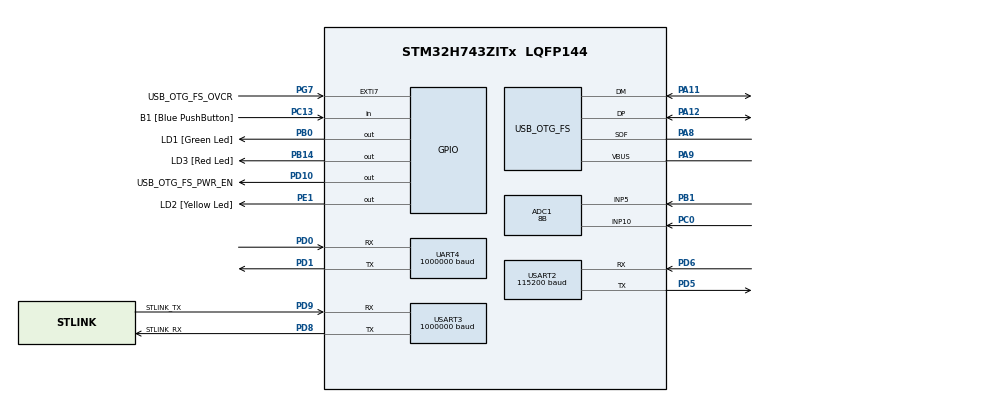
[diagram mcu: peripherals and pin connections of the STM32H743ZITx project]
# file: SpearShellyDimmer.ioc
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ADC1.Channel-0\#ChannelRegularConversion=ADC_CHANNEL_10
ADC1.Channel-1\#ChannelRegularConversion=ADC_CHANNEL_5
ADC1.ClockPrescaler=ADC_CLOCK_ASYNC_DIV8
ADC1.ContinuousConvMode=ENABLE
ADC1.ConversionDataManagement=ADC_CONVERSIONDATA_DMA_ONESHOT
ADC1.NbrOfConversion=2
ADC1.NbrOfConversionFlag=1
ADC1.OffsetNumber-0\#ChannelRegularConversion=ADC_OFFSET_NONE
ADC1.OffsetNumber-1\#ChannelRegularConversion=ADC_OFFSET_NONE
ADC1.OffsetSignedSaturation-0\#ChannelRegularConversion=DISABLE
ADC1.OffsetSignedSaturation-1\#ChannelRegularConversion=DISABLE
ADC1.Rank-0\#ChannelRegularConversion=1
ADC1.Rank-1\#ChannelRegularConversion=2
ADC1.Resolution=ADC_RESOLUTION_8B
ADC1.SamplingTime-0\#ChannelRegularConversion=ADC_SAMPLETIME_2CYCLES_5
ADC1.SamplingTime-1\#ChannelRegularConversion=ADC_SAMPLETIME_2CYCLES_5
ADC1.master=1
CORTEX_M7.CPU_DCache=Enabled
CORTEX_M7.CPU_ICache=Enabled
Dma.ADC1.0.Direction=DMA_PERIPH_TO_MEMORY
Dma.ADC1.0.EventEnable=DISABLE
Dma.ADC1.0.FIFOMode=DMA_FIFOMODE_DISABLE
Dma.ADC1.0.Instance=DMA1_Stream1
Dma.ADC1.0.MemDataAlignment=DMA_MDATAALIGN_HALFWORD
Dma.ADC1.0.MemInc=DMA_MINC_ENABLE
Dma.ADC1.0.Mode=DMA_NORMAL
Dma.ADC1.0.PeriphDataAlignment=DMA_PDATAALIGN_HALFWORD
Dma.ADC1.0.PeriphInc=DMA_PINC_DISABLE
Dma.ADC1.0.Polarity=HAL_DMAMUX_REQ_GEN_RISING
Dma.ADC1.0.Priority=DMA_PRIORITY_LOW
Dma.ADC1.0.RequestNumber=1
Dma.ADC1.0.SignalID=NONE
Dma.ADC1.0.SyncEnable=DISABLE
Dma.ADC1.0.SyncPolarity=HAL_DMAMUX_SYNC_NO_EVENT
Dma.ADC1.0.SyncRequestNumber=1
Dma.ADC1.0.SyncSignalID=NONE
Dma.Request0=ADC1
Mcu.Family=STM32H7
Mcu.Name=STM32H743ZITx
Mcu.Package=LQFP144
NVIC.DMA1_Stream1_IRQn=true\:0\:0\:false\:false\:true\:false\:true\:true
NVIC.OTG_FS_IRQn=true\:5\:0\:true\:false\:true\:false\:true\:true
NVIC.PriorityGroup=NVIC_PRIORITYGROUP_4
NVIC.TIM17_IRQn=true\:15\:0\:false\:false\:true\:false\:true\:true
NVIC.TIM3_IRQn=true\:0\:0\:false\:false\:true\:true\:true\:true
NVIC.TimeBase=TIM17_IRQn
NVIC.TimeBaseIP=TIM17
NVIC.UART4_IRQn=true\:6\:0\:true\:false\:true\:true\:true\:true
NVIC.USART2_IRQn=true\:6\:0\:true\:false\:true\:true\:true\:true
PA1.Signal=ETH_REF_CLK
PA11.Mode=Device_Only
PA11.Signal=USB_OTG_FS_DM
PA12.Mode=Device_Only
PA12.Signal=USB_OTG_FS_DP
PA2.Signal=ETH_MDIO
PA7.Signal=ETH_CRS_DV
PA8.Mode=Activate_SOF_FS
PA8.Signal=USB_OTG_FS_SOF
PA9.Mode=Activate_VBUS
PA9.Signal=USB_OTG_FS_VBUS
PB0.GPIO_Label=LD1 [Green Led]
PB0.Signal=GPIO_Output
PB1.Signal=ADCx_INP5
PB13.Signal=ETH_TXD1
PB14.GPIO_Label=LD3 [Red Led]
PB14.Signal=GPIO_Output
PC0.Signal=ADCx_INP10
PC1.Signal=ETH_MDC
PC13.GPIO_Label=B1 [Blue PushButton]
PC13.Signal=GPIO_Input
PC14-OSC32_IN\ (OSC32_IN).Mode=LSE-External-Oscillator
PC14-OSC32_IN\ (OSC32_IN).Signal=RCC_OSC32_IN
PC15-OSC32_OUT\ (OSC32_OUT).Mode=LSE-External-Oscillator
PC15-OSC32_OUT\ (OSC32_OUT).Signal=RCC_OSC32_OUT
PC4.Signal=ETH_RXD0
PC5.Signal=ETH_RXD1
PD0.Mode=Asynchronous
PD0.Signal=UART4_RX
PD1.Mode=Asynchronous
PD1.Signal=UART4_TX
PD10.GPIO_Label=USB_OTG_FS_PWR_EN
PD10.Signal=GPIO_Output
PD5.Mode=Asynchronous
PD5.Signal=USART2_TX
PD6.Mode=Asynchronous
PD6.Signal=USART2_RX
PD8.GPIO_Label=STLINK_RX
PD8.Mode=Asynchronous
PD8.Signal=USART3_TX
PD9.GPIO_Label=STLINK_TX
PD9.Mode=Asynchronous
PD9.Signal=USART3_RX
PE1.GPIO_Label=LD2 [Yellow Led]
PE1.Signal=GPIO_Output
PG11.Signal=ETH_TX_EN
PG13.Signal=ETH_TXD0
PG7.GPIO_Label=USB_OTG_FS_OVCR
PG7.Signal=GPXTI7
PH0-OSC_IN\ (PH0).Mode=HSE-External-Clock-Source
PH0-OSC_IN\ (PH0).Signal=RCC_OSC_IN
PH1-OSC_OUT\ (PH1).Signal=RCC_OSC_OUT
ProjectManager.HeapSize=0x200
ProjectManager.StackSize=0x400
ProjectManager.TargetToolchain=STM32CubeIDE
RCC.ADCFreq_Value=76000000
RCC.APB1Freq_Value=120000000
RCC.APB2Freq_Value=120000000
RCC.APB3Freq_Value=120000000
RCC.APB4Freq_Value=120000000
RCC.CortexFreq_Value=480000000
RCC.D1PPRE=RCC_APB3_DIV2
RCC.D2PPRE1=RCC_APB1_DIV2
RCC.D2PPRE2=RCC_APB2_DIV2
RCC.D3PPRE=RCC_APB4_DIV2
RCC.DIVM1=1
RCC.DIVM2=1
RCC.DIVN1=120
RCC.DIVN2=19
RCC.HCLKFreq_Value=240000000
RCC.HPRE=RCC_HCLK_DIV2
RCC.HSE_VALUE=8000000
RCC.PLL2FRACN=0
RCC.PLL3FRACN=0
RCC.PLLFRACN=0
RCC.PLLSourceVirtual=RCC_PLLSOURCE_HSE
RCC.PWR_Regulator_Voltage_Scale=PWR_REGULATOR_VOLTAGE_SCALE0
RCC.SYSCLKFreq_VALUE=480000000
RCC.SYSCLKSource=RCC_SYSCLKSOURCE_PLLCLK
RCC.USBCLockSelection=RCC_USBCLKSOURCE_HSI48
RCC.USBFreq_Value=48000000
SH.ADCx_INP10.0=ADC1_INP10,IN10-Single-Ended
SH.ADCx_INP5.0=ADC1_INP5,IN5-Single-Ended
TIM3.AutoReloadPreload=TIM_AUTORELOAD_PRELOAD_ENABLE
TIM3.Channel-Output\ Compare1\ No\ Output=TIM_CHANNEL_1
TIM3.Period=10
TIM3.Prescaler=4800
TIM3.Pulse-Output\ Compare1\ No\ Output=5
UART4.BaudRate=1000000
UART4.FIFOMode=FIFOMODE_DISABLE
UART4.Mode=MODE_TX_RX
USART2.BaudRate=115200
USART2.Mode=MODE_TX_RX
USART2.VirtualMode-Asynchronous=VM_ASYNC
USART3.BaudRate=1000000
USART3.VirtualMode-Asynchronous=VM_ASYNC
USB_DEVICE.CLASS_NAME_FS=CDC
USB_DEVICE.USBD_MAX_NUM_INTERFACES-CDC_FS=1
USB_DEVICE.VirtualMode-CDC_FS=Cdc
USB_DEVICE.VirtualModeFS=Cdc_FS
USB_OTG_FS.VirtualMode=Device_Only
VP_SYS_VS_tim17.Mode=TIM17
VP_TIM3_VS_ClockSourceINT.Mode=Internal
VP_TIM3_VS_no_output1.Mode=Output Compare1 No Output
VP_USB_DEVICE_VS_USB_DEVICE_CDC_FS.Mode=CDC_FS
board=NUCLEO-H743ZI2

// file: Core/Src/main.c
/* USER CODE BEGIN Header */
/**
  ******************************************************************************
  * @file           : main.c
  * @brief          : Main program body
  ******************************************************************************
  * @attention
  *
  * <h2><center>&copy; Copyright (c) 2022 STMicroelectronics.
  * All rights reserved.</center></h2>
  *
  * This software component is licensed by ST under BSD 3-Clause license,
  * the "License"; You may not use this file except in compliance with the
  * License. You may obtain a copy of the License at:
  *                        opensource.org/licenses/BSD-3-Clause
  *
  ******************************************************************************
  */
/* USER CODE END Header */
#include "main.h"
#include "usb_device.h"

/* USER CODE BEGIN Includes */
#include "monitor.h"
#include "shelly.h"
/* USER CODE END Includes */

ADC_HandleTypeDef hadc1;
DMA_HandleTypeDef hdma_adc1;

TIM_HandleTypeDef htim3;

UART_HandleTypeDef huart4;
UART_HandleTypeDef huart2;
UART_HandleTypeDef huart3;

void SystemClock_Config(void);
static void MX_GPIO_Init(void);
static void MX_USART3_UART_Init(void);
static void MX_DMA_Init(void);
static void MX_UART4_Init(void);
static void MX_USART2_UART_Init(void);
static void MX_TIM3_Init(void);
static void MX_ADC1_Init(void);

/* USER CODE BEGIN 0 */
void __io_putchar(uint8_t ch) {
HAL_UART_Transmit(&huart3, &ch, 1, 1);
}
/* USER CODE END 0 */

int main(void)
{

  /* Enable I-Cache---------------------------------------------------------*/
  SCB_EnableICache();

  /* Enable D-Cache---------------------------------------------------------*/
  SCB_EnableDCache();

  /* MCU Configuration--------------------------------------------------------*/

  /* Reset of all peripherals, Initializes the Flash interface and the Systick. */
  HAL_Init();

  /* Configure the system clock */
  SystemClock_Config();

  /* Initialize all configured peripherals */
  MX_GPIO_Init();
  MX_USART3_UART_Init();
  MX_DMA_Init();
  MX_UART4_Init();
  MX_USART2_UART_Init();
  MX_USB_DEVICE_Init();
  MX_TIM3_Init();
  MX_ADC1_Init();
  /* USER CODE BEGIN 2 */

  //entry point of the application it will create the
  //monitor and target and start the kernel
  //core_main();
  app_main();

  /* USER CODE END 2 */

  /* Infinite loop */
  while (1)
  {

  }
}

void SystemClock_Config(void)
{
  RCC_OscInitTypeDef RCC_OscInitStruct = {0};
  RCC_ClkInitTypeDef RCC_ClkInitStruct = {0};

  /** Supply configuration update enable
  */
  HAL_PWREx_ConfigSupply(PWR_LDO_SUPPLY);
  /** Configure the main internal regulator output voltage
  */
  __HAL_PWR_VOLTAGESCALING_CONFIG(PWR_REGULATOR_VOLTAGE_SCALE0);

  while(!__HAL_PWR_GET_FLAG(PWR_FLAG_VOSRDY)) {}
  /** Macro to configure the PLL clock source
  */
  __HAL_RCC_PLL_PLLSOURCE_CONFIG(RCC_PLLSOURCE_HSE);
  /** Initializes the RCC Oscillators according to the specified parameters
  * in the RCC_OscInitTypeDef structure.
  */
  RCC_OscInitStruct.OscillatorType = RCC_OSCILLATORTYPE_HSI48|RCC_OSCILLATORTYPE_HSE;
  RCC_OscInitStruct.HSEState = RCC_HSE_BYPASS;
  RCC_OscInitStruct.HSI48State = RCC_HSI48_ON;
  RCC_OscInitStruct.PLL.PLLState = RCC_PLL_ON;
  RCC_OscInitStruct.PLL.PLLSource = RCC_PLLSOURCE_HSE;
  RCC_OscInitStruct.PLL.PLLM = 1;
  RCC_OscInitStruct.PLL.PLLN = 120;
  RCC_OscInitStruct.PLL.PLLP = 2;
  RCC_OscInitStruct.PLL.PLLQ = 2;
  RCC_OscInitStruct.PLL.PLLR = 2;
  RCC_OscInitStruct.PLL.PLLRGE = RCC_PLL1VCIRANGE_3;
  RCC_OscInitStruct.PLL.PLLVCOSEL = RCC_PLL1VCOWIDE;
  RCC_OscInitStruct.PLL.PLLFRACN = 0;
  if (HAL_RCC_OscConfig(&RCC_OscInitStruct) != HAL_OK)
  {
    Error_Handler();
  }
  /** Initializes the CPU, AHB and APB buses clocks
  */
  RCC_ClkInitStruct.ClockType = RCC_CLOCKTYPE_HCLK|RCC_CLOCKTYPE_SYSCLK
                              |RCC_CLOCKTYPE_PCLK1|RCC_CLOCKTYPE_PCLK2
                              |RCC_CLOCKTYPE_D3PCLK1|RCC_CLOCKTYPE_D1PCLK1;
  RCC_ClkInitStruct.SYSCLKSource = RCC_SYSCLKSOURCE_PLLCLK;
  RCC_ClkInitStruct.SYSCLKDivider = RCC_SYSCLK_DIV1;
  RCC_ClkInitStruct.AHBCLKDivider = RCC_HCLK_DIV2;
  RCC_ClkInitStruct.APB3CLKDivider = RCC_APB3_DIV2;
  RCC_ClkInitStruct.APB1CLKDivider = RCC_APB1_DIV2;
  RCC_ClkInitStruct.APB2CLKDivider = RCC_APB2_DIV2;
  RCC_ClkInitStruct.APB4CLKDivider = RCC_APB4_DIV2;

  if (HAL_RCC_ClockConfig(&RCC_ClkInitStruct, FLASH_LATENCY_4) != HAL_OK)
  {
    Error_Handler();
  }
}

static void MX_ADC1_Init(void)
{

  ADC_MultiModeTypeDef multimode = {0};
  ADC_ChannelConfTypeDef sConfig = {0};

  /** Common config
  */
  hadc1.Instance = ADC1;
  hadc1.Init.ClockPrescaler = ADC_CLOCK_ASYNC_DIV8;
  hadc1.Init.Resolution = ADC_RESOLUTION_8B;
  hadc1.Init.ScanConvMode = ADC_SCAN_ENABLE;
  hadc1.Init.EOCSelection = ADC_EOC_SINGLE_CONV;
  hadc1.Init.LowPowerAutoWait = DISABLE;
  hadc1.Init.ContinuousConvMode = ENABLE;
  hadc1.Init.NbrOfConversion = 2;
  hadc1.Init.DiscontinuousConvMode = DISABLE;
  hadc1.Init.ExternalTrigConv = ADC_SOFTWARE_START;
  hadc1.Init.ExternalTrigConvEdge = ADC_EXTERNALTRIGCONVEDGE_NONE;
  hadc1.Init.ConversionDataManagement = ADC_CONVERSIONDATA_DMA_ONESHOT;
  hadc1.Init.Overrun = ADC_OVR_DATA_PRESERVED;
  hadc1.Init.LeftBitShift = ADC_LEFTBITSHIFT_NONE;
  hadc1.Init.OversamplingMode = DISABLE;
  if (HAL_ADC_Init(&hadc1) != HAL_OK)
  {
    Error_Handler();
  }
  /** Configure the ADC multi-mode
  */
  multimode.Mode = ADC_MODE_INDEPENDENT;
  if (HAL_ADCEx_MultiModeConfigChannel(&hadc1, &multimode) != HAL_OK)
  {
    Error_Handler();
  }
  /** Configure Regular Channel
  */
  sConfig.Channel = ADC_CHANNEL_10;
  sConfig.Rank = ADC_REGULAR_RANK_1;
  sConfig.SamplingTime = ADC_SAMPLETIME_2CYCLES_5;
  sConfig.SingleDiff = ADC_SINGLE_ENDED;
  sConfig.OffsetNumber = ADC_OFFSET_NONE;
  sConfig.Offset = 0;
  sConfig.OffsetSignedSaturation = DISABLE;
  if (HAL_ADC_ConfigChannel(&hadc1, &sConfig) != HAL_OK)
  {
    Error_Handler();
  }
  /** Configure Regular Channel
  */
  sConfig.Channel = ADC_CHANNEL_5;
  sConfig.Rank = ADC_REGULAR_RANK_2;
  if (HAL_ADC_ConfigChannel(&hadc1, &sConfig) != HAL_OK)
  {
    Error_Handler();
  }

}

static void MX_TIM3_Init(void)
{

  TIM_ClockConfigTypeDef sClockSourceConfig = {0};
  TIM_MasterConfigTypeDef sMasterConfig = {0};
  TIM_OC_InitTypeDef sConfigOC = {0};

  htim3.Instance = TIM3;
  htim3.Init.Prescaler = 4800;
  htim3.Init.CounterMode = TIM_COUNTERMODE_UP;
  htim3.Init.Period = 10;
  htim3.Init.ClockDivision = TIM_CLOCKDIVISION_DIV1;
  htim3.Init.AutoReloadPreload = TIM_AUTORELOAD_PRELOAD_ENABLE;
  if (HAL_TIM_Base_Init(&htim3) != HAL_OK)
  {
    Error_Handler();
  }
  sClockSourceConfig.ClockSource = TIM_CLOCKSOURCE_INTERNAL;
  if (HAL_TIM_ConfigClockSource(&htim3, &sClockSourceConfig) != HAL_OK)
  {
    Error_Handler();
  }
  if (HAL_TIM_OC_Init(&htim3) != HAL_OK)
  {
    Error_Handler();
  }
  sMasterConfig.MasterOutputTrigger = TIM_TRGO_RESET;
  sMasterConfig.MasterSlaveMode = TIM_MASTERSLAVEMODE_DISABLE;
  if (HAL_TIMEx_MasterConfigSynchronization(&htim3, &sMasterConfig) != HAL_OK)
  {
    Error_Handler();
  }
  sConfigOC.OCMode = TIM_OCMODE_TIMING;
  sConfigOC.Pulse = 5;
  sConfigOC.OCPolarity = TIM_OCPOLARITY_HIGH;
  sConfigOC.OCFastMode = TIM_OCFAST_DISABLE;
  if (HAL_TIM_OC_ConfigChannel(&htim3, &sConfigOC, TIM_CHANNEL_1) != HAL_OK)
  {
    Error_Handler();
  }

}

static void MX_UART4_Init(void)
{

  huart4.Instance = UART4;
  huart4.Init.BaudRate = 1000000;
  huart4.Init.WordLength = UART_WORDLENGTH_8B;
  huart4.Init.StopBits = UART_STOPBITS_1;
  huart4.Init.Parity = UART_PARITY_NONE;
  huart4.Init.Mode = UART_MODE_TX_RX;
  huart4.Init.HwFlowCtl = UART_HWCONTROL_NONE;
  huart4.Init.OverSampling = UART_OVERSAMPLING_16;
  huart4.Init.OneBitSampling = UART_ONE_BIT_SAMPLE_DISABLE;
  huart4.Init.ClockPrescaler = UART_PRESCALER_DIV1;
  huart4.AdvancedInit.AdvFeatureInit = UART_ADVFEATURE_NO_INIT;
  if (HAL_UART_Init(&huart4) != HAL_OK)
  {
    Error_Handler();
  }
  if (HAL_UARTEx_SetTxFifoThreshold(&huart4, UART_TXFIFO_THRESHOLD_1_8) != HAL_OK)
  {
    Error_Handler();
  }
  if (HAL_UARTEx_SetRxFifoThreshold(&huart4, UART_RXFIFO_THRESHOLD_1_8) != HAL_OK)
  {
    Error_Handler();
  }
  if (HAL_UARTEx_DisableFifoMode(&huart4) != HAL_OK)
  {
    Error_Handler();
  }

}

static void MX_USART2_UART_Init(void)
{

  huart2.Instance = USART2;
  huart2.Init.BaudRate = 115200;
  huart2.Init.WordLength = UART_WORDLENGTH_8B;
  huart2.Init.StopBits = UART_STOPBITS_1;
  huart2.Init.Parity = UART_PARITY_NONE;
  huart2.Init.Mode = UART_MODE_TX_RX;
  huart2.Init.HwFlowCtl = UART_HWCONTROL_NONE;
  huart2.Init.OverSampling = UART_OVERSAMPLING_16;
  huart2.Init.OneBitSampling = UART_ONE_BIT_SAMPLE_DISABLE;
  huart2.Init.ClockPrescaler = UART_PRESCALER_DIV1;
  huart2.AdvancedInit.AdvFeatureInit = UART_ADVFEATURE_NO_INIT;
  if (HAL_UART_Init(&huart2) != HAL_OK)
  {
    Error_Handler();
  }
  if (HAL_UARTEx_SetTxFifoThreshold(&huart2, UART_TXFIFO_THRESHOLD_1_8) != HAL_OK)
  {
    Error_Handler();
  }
  if (HAL_UARTEx_SetRxFifoThreshold(&huart2, UART_RXFIFO_THRESHOLD_1_8) != HAL_OK)
  {
    Error_Handler();
  }
  if (HAL_UARTEx_DisableFifoMode(&huart2) != HAL_OK)
  {
    Error_Handler();
  }

}

static void MX_USART3_UART_Init(void)
{

  huart3.Instance = USART3;
  huart3.Init.BaudRate = 1000000;
  huart3.Init.WordLength = UART_WORDLENGTH_8B;
  huart3.Init.StopBits = UART_STOPBITS_1;
  huart3.Init.Parity = UART_PARITY_NONE;
  huart3.Init.Mode = UART_MODE_TX_RX;
  huart3.Init.HwFlowCtl = UART_HWCONTROL_NONE;
  huart3.Init.OverSampling = UART_OVERSAMPLING_16;
  huart3.Init.OneBitSampling = UART_ONE_BIT_SAMPLE_DISABLE;
  huart3.Init.ClockPrescaler = UART_PRESCALER_DIV1;
  huart3.AdvancedInit.AdvFeatureInit = UART_ADVFEATURE_NO_INIT;
  if (HAL_UART_Init(&huart3) != HAL_OK)
  {
    Error_Handler();
  }
  if (HAL_UARTEx_SetTxFifoThreshold(&huart3, UART_TXFIFO_THRESHOLD_1_8) != HAL_OK)
  {
    Error_Handler();
  }
  if (HAL_UARTEx_SetRxFifoThreshold(&huart3, UART_RXFIFO_THRESHOLD_1_8) != HAL_OK)
  {
    Error_Handler();
  }
  if (HAL_UARTEx_DisableFifoMode(&huart3) != HAL_OK)
  {
    Error_Handler();
  }

}

static void MX_DMA_Init(void)
{

  /* DMA controller clock enable */
  __HAL_RCC_DMA1_CLK_ENABLE();

  /* DMA interrupt init */
  /* DMA1_Stream1_IRQn interrupt configuration */
  HAL_NVIC_SetPriority(DMA1_Stream1_IRQn, 0, 0);
  HAL_NVIC_EnableIRQ(DMA1_Stream1_IRQn);

}

static void MX_GPIO_Init(void)
{
  GPIO_InitTypeDef GPIO_InitStruct = {0};

  /* GPIO Ports Clock Enable */
  __HAL_RCC_GPIOC_CLK_ENABLE();
  __HAL_RCC_GPIOH_CLK_ENABLE();
  __HAL_RCC_GPIOA_CLK_ENABLE();
  __HAL_RCC_GPIOB_CLK_ENABLE();
  __HAL_RCC_GPIOD_CLK_ENABLE();
  __HAL_RCC_GPIOG_CLK_ENABLE();
  __HAL_RCC_GPIOE_CLK_ENABLE();

  /*Configure GPIO pin Output Level */
  HAL_GPIO_WritePin(GPIOB, LD1_Pin|LD3_Pin, GPIO_PIN_RESET);

  /*Configure GPIO pin Output Level */
  HAL_GPIO_WritePin(USB_OTG_FS_PWR_EN_GPIO_Port, USB_OTG_FS_PWR_EN_Pin, GPIO_PIN_RESET);

  /*Configure GPIO pin Output Level */
  HAL_GPIO_WritePin(LD2_GPIO_Port, LD2_Pin, GPIO_PIN_RESET);

  /*Configure GPIO pin : B1_Pin */
  GPIO_InitStruct.Pin = B1_Pin;
  GPIO_InitStruct.Mode = GPIO_MODE_INPUT;
  GPIO_InitStruct.Pull = GPIO_NOPULL;
  HAL_GPIO_Init(B1_GPIO_Port, &GPIO_InitStruct);

  /*Configure GPIO pins : PC1 PC4 PC5 */
  GPIO_InitStruct.Pin = GPIO_PIN_1|GPIO_PIN_4|GPIO_PIN_5;
  GPIO_InitStruct.Mode = GPIO_MODE_AF_PP;
  GPIO_InitStruct.Pull = GPIO_NOPULL;
  GPIO_InitStruct.Speed = GPIO_SPEED_FREQ_LOW;
  GPIO_InitStruct.Alternate = GPIO_AF11_ETH;
  HAL_GPIO_Init(GPIOC, &GPIO_InitStruct);

  /*Configure GPIO pins : PA1 PA2 PA7 */
  GPIO_InitStruct.Pin = GPIO_PIN_1|GPIO_PIN_2|GPIO_PIN_7;
  GPIO_InitStruct.Mode = GPIO_MODE_AF_PP;
  GPIO_InitStruct.Pull = GPIO_NOPULL;
  GPIO_InitStruct.Speed = GPIO_SPEED_FREQ_LOW;
  GPIO_InitStruct.Alternate = GPIO_AF11_ETH;
  HAL_GPIO_Init(GPIOA, &GPIO_InitStruct);

  /*Configure GPIO pins : LD1_Pin LD3_Pin */
  GPIO_InitStruct.Pin = LD1_Pin|LD3_Pin;
  GPIO_InitStruct.Mode = GPIO_MODE_OUTPUT_PP;
  GPIO_InitStruct.Pull = GPIO_NOPULL;
  GPIO_InitStruct.Speed = GPIO_SPEED_FREQ_LOW;
  HAL_GPIO_Init(GPIOB, &GPIO_InitStruct);

  /*Configure GPIO pin : PB13 */
  GPIO_InitStruct.Pin = GPIO_PIN_13;
  GPIO_InitStruct.Mode = GPIO_MODE_AF_PP;
  GPIO_InitStruct.Pull = GPIO_NOPULL;
  GPIO_InitStruct.Speed = GPIO_SPEED_FREQ_LOW;
  GPIO_InitStruct.Alternate = GPIO_AF11_ETH;
  HAL_GPIO_Init(GPIOB, &GPIO_InitStruct);

  /*Configure GPIO pin : USB_OTG_FS_PWR_EN_Pin */
  GPIO_InitStruct.Pin = USB_OTG_FS_PWR_EN_Pin;
  GPIO_InitStruct.Mode = GPIO_MODE_OUTPUT_PP;
  GPIO_InitStruct.Pull = GPIO_NOPULL;
  GPIO_InitStruct.Speed = GPIO_SPEED_FREQ_LOW;
  HAL_GPIO_Init(USB_OTG_FS_PWR_EN_GPIO_Port, &GPIO_InitStruct);

  /*Configure GPIO pin : USB_OTG_FS_OVCR_Pin */
  GPIO_InitStruct.Pin = USB_OTG_FS_OVCR_Pin;
  GPIO_InitStruct.Mode = GPIO_MODE_IT_RISING;
  GPIO_InitStruct.Pull = GPIO_NOPULL;
  HAL_GPIO_Init(USB_OTG_FS_OVCR_GPIO_Port, &GPIO_InitStruct);

  /*Configure GPIO pins : PG11 PG13 */
  GPIO_InitStruct.Pin = GPIO_PIN_11|GPIO_PIN_13;
  GPIO_InitStruct.Mode = GPIO_MODE_AF_PP;
  GPIO_InitStruct.Pull = GPIO_NOPULL;
  GPIO_InitStruct.Speed = GPIO_SPEED_FREQ_LOW;
  GPIO_InitStruct.Alternate = GPIO_AF11_ETH;
  HAL_GPIO_Init(GPIOG, &GPIO_InitStruct);

  /*Configure GPIO pin : LD2_Pin */
  GPIO_InitStruct.Pin = LD2_Pin;
  GPIO_InitStruct.Mode = GPIO_MODE_OUTPUT_PP;
  GPIO_InitStruct.Pull = GPIO_NOPULL;
  GPIO_InitStruct.Speed = GPIO_SPEED_FREQ_LOW;
  HAL_GPIO_Init(LD2_GPIO_Port, &GPIO_InitStruct);

}

void HAL_TIM_PeriodElapsedCallback(TIM_HandleTypeDef *htim)
{
  if (htim->Instance == TIM17) {
    HAL_IncTick();
  }
  /* USER CODE BEGIN Callback 1 */
  if (htim == &htim3)
  {
	  tim3_isr();
  }

  /* USER CODE END Callback 1 */
}

void Error_Handler(void)
{
  __disable_irq();
  while (1)
  {
  }
}

/************************ (C) COPYRIGHT STMicroelectronics *****END OF FILE****/
